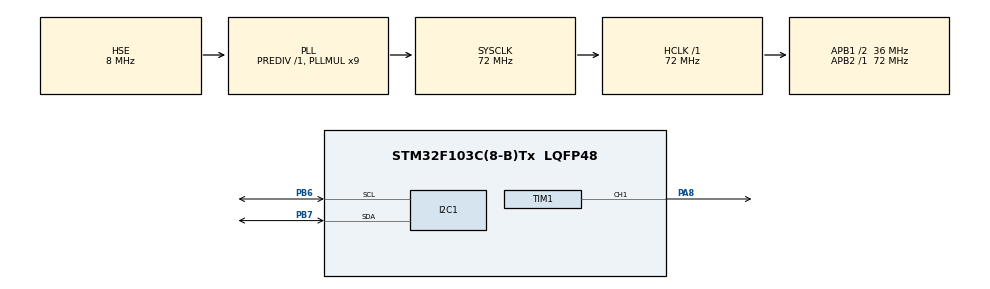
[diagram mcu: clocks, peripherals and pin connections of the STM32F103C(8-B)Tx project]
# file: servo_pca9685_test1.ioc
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I2C1.I2C_Mode=I2C_Fast
Mcu.Family=STM32F1
Mcu.Name=STM32F103C(8-B)Tx
Mcu.Package=LQFP48
NVIC.PriorityGroup=NVIC_PRIORITYGROUP_4
NVIC.TIM2_IRQn=true\:0\:0\:false\:false\:true\:true\:true\:true
PA13.Mode=Serial_Wire
PA13.Signal=SYS_JTMS-SWDIO
PA14.Mode=Serial_Wire
PA14.Signal=SYS_JTCK-SWCLK
PA8.Signal=S_TIM1_CH1
PB6.Mode=I2C
PB6.Signal=I2C1_SCL
PB7.Mode=I2C
PB7.Signal=I2C1_SDA
PD0-OSC_IN.Mode=HSE-External-Oscillator
PD0-OSC_IN.Signal=RCC_OSC_IN
PD1-OSC_OUT.Mode=HSE-External-Oscillator
PD1-OSC_OUT.Signal=RCC_OSC_OUT
ProjectManager.HeapSize=0x200
ProjectManager.StackSize=0x400
ProjectManager.TargetToolchain=STM32CubeIDE
RCC.AHBFreq_Value=72000000
RCC.APB1CLKDivider=RCC_HCLK_DIV2
RCC.APB1Freq_Value=36000000
RCC.APB1TimFreq_Value=72000000
RCC.APB2Freq_Value=72000000
RCC.APB2TimFreq_Value=72000000
RCC.HCLKFreq_Value=72000000
RCC.PLLMUL=RCC_PLL_MUL9
RCC.PLLSourceVirtual=RCC_PLLSOURCE_HSE
RCC.SYSCLKFreq_VALUE=72000000
RCC.SYSCLKSource=RCC_SYSCLKSOURCE_PLLCLK
RCC.USBFreq_Value=72000000
SH.S_TIM1_CH1.0=TIM1_CH1,PWM Generation1 CH1
TIM1.AutoReloadPreload=TIM_AUTORELOAD_PRELOAD_ENABLE
TIM1.Channel-PWM\ Generation1\ CH1=TIM_CHANNEL_1
TIM1.Period=9999
TIM1.Prescaler=15
TIM2.Period=999
TIM2.Prescaler=71
VP_TIM2_VS_ClockSourceINT.Mode=Internal
board=custom

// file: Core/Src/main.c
/* USER CODE BEGIN Header */
/**
  ******************************************************************************
  * @file           : main.c
  * @brief          : Main program body
  ******************************************************************************
  * @attention
  *
  * Copyright (c) 2023 STMicroelectronics.
  * All rights reserved.
  *
  * This software is licensed under terms that can be found in the LICENSE file
  * in the root directory of this software component.
  * If no LICENSE file comes with this software, it is provided AS-IS.
  *
  ******************************************************************************
  */
/* USER CODE END Header */
#include "main.h"
#include "i2c.h"
#include "tim.h"
#include "gpio.h"

/* USER CODE BEGIN Includes */
#include "pca9685.h"
/* USER CODE END Includes */

/* USER CODE BEGIN PTD */
#define SERVO_COUNT	5
/* USER CODE END PTD */

/* USER CODE BEGIN PV */
uint8_t ActiveServo;
uint8_t Angle;
int pick_data;
uint16_t degree = 0;
int i =0;
uint16_t pwm;

/* USER CODE END PV */

void SystemClock_Config(void);
/* USER CODE BEGIN PFP */
float map(float Input, float Min_Input, float Max_Input, float Min_Output,
		float Max_Output) {

	return (float) ((Input - Min_Input) * (Max_Output - Min_Output)
			/ (Max_Input - Min_Input) + Min_Output);
}
void servo_move(uint8_t start,uint8_t stop,uint8_t i) // i is channel of servo
{
	for (uint8_t Angle = start;  Angle < stop; Angle++) {
		PCA9685_SetServoAngle(i, Angle);
	}

}
void servo_back(uint8_t start,uint8_t stop,uint8_t i) // i is channel of servo
{
	for (uint8_t Angle = start; Angle > stop; Angle--) {
			PCA9685_SetServoAngle(i, Angle);
		}
}
void servo_rotation(uint16_t deg) // degree input from 0 to 180
{
	pwm = map(deg,0,180,1900,9600);
	TIM1->CCR1 = pwm;
}

/* USER CODE END PFP */

int main(void)
{

  /* MCU Configuration--------------------------------------------------------*/

  /* Reset of all peripherals, Initializes the Flash interface and the Systick. */
  HAL_Init();

  /* Configure the system clock */
  SystemClock_Config();

  /* Initialize all configured peripherals */
  MX_GPIO_Init();
  MX_I2C1_Init();
  MX_TIM2_Init();
  MX_TIM1_Init();
  /* USER CODE BEGIN 2 */
  HAL_TIM_PWM_Start(&htim1, TIM_CHANNEL_1);
  	HAL_TIM_Base_Start_IT(&htim2);
	PCA9685_Init(&hi2c1);
	PCA9685_SetServoAngle(0, 0);
	PCA9685_SetServoAngle(1, 0);
	PCA9685_SetServoAngle(2, 0);
	PCA9685_SetServoAngle(3, 0);
	PCA9685_SetServoAngle(4, 0);

	HAL_Delay(2000);
  /* USER CODE END 2 */

  /* Infinite loop */
  while (1)
  {

    /* USER CODE BEGIN 3 */

	/** Control servo through timer pwm **/
	  servo_rotation(degree);
	  HAL_Delay(50);

	/** Control Servo through I2C(PCA9685) **/
	  	  servo_move(25, 90, 0);
	  	HAL_Delay(2000);
	  	servo_back(90, 25, 0);
	  	HAL_Delay(2000);
  }

  /* USER CODE END 3 */
}

void SystemClock_Config(void)
{
  RCC_OscInitTypeDef RCC_OscInitStruct = {0};
  RCC_ClkInitTypeDef RCC_ClkInitStruct = {0};

  /** Initializes the RCC Oscillators according to the specified parameters
  * in the RCC_OscInitTypeDef structure.
  */
  RCC_OscInitStruct.OscillatorType = RCC_OSCILLATORTYPE_HSE;
  RCC_OscInitStruct.HSEState = RCC_HSE_ON;
  RCC_OscInitStruct.HSEPredivValue = RCC_HSE_PREDIV_DIV1;
  RCC_OscInitStruct.HSIState = RCC_HSI_ON;
  RCC_OscInitStruct.PLL.PLLState = RCC_PLL_ON;
  RCC_OscInitStruct.PLL.PLLSource = RCC_PLLSOURCE_HSE;
  RCC_OscInitStruct.PLL.PLLMUL = RCC_PLL_MUL9;
  if (HAL_RCC_OscConfig(&RCC_OscInitStruct) != HAL_OK)
  {
    Error_Handler();
  }

  /** Initializes the CPU, AHB and APB buses clocks
  */
  RCC_ClkInitStruct.ClockType = RCC_CLOCKTYPE_HCLK|RCC_CLOCKTYPE_SYSCLK
                              |RCC_CLOCKTYPE_PCLK1|RCC_CLOCKTYPE_PCLK2;
  RCC_ClkInitStruct.SYSCLKSource = RCC_SYSCLKSOURCE_PLLCLK;
  RCC_ClkInitStruct.AHBCLKDivider = RCC_SYSCLK_DIV1;
  RCC_ClkInitStruct.APB1CLKDivider = RCC_HCLK_DIV2;
  RCC_ClkInitStruct.APB2CLKDivider = RCC_HCLK_DIV1;

  if (HAL_RCC_ClockConfig(&RCC_ClkInitStruct, FLASH_LATENCY_2) != HAL_OK)
  {
    Error_Handler();
  }
}

/* USER CODE BEGIN 4 */
//void HAL_TIM_PeriodElapsedCallback(TIM_HandleTypeDef *htim)
//{
//	//In 10ms IMU one time
//	if (htim->Instance == TIM2) {
//
//		for (Angle= 0; Angle < 180; Angle++)
//	    {
//		  	PCA9685_SetServoAngle(0, Angle);
//		}
//	}
//}

/* USER CODE END 4 */

void Error_Handler(void)
{
  __disable_irq();
  while (1)
  {
  }
}
